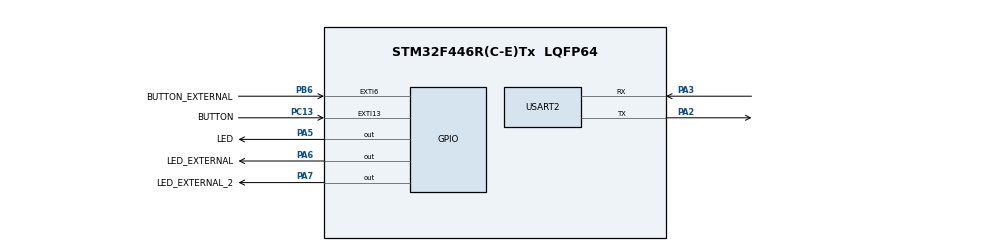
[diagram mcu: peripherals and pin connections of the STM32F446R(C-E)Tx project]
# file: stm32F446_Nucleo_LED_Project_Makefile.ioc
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Mcu.Family=STM32F4
Mcu.Name=STM32F446R(C-E)Tx
Mcu.Package=LQFP64
NVIC.EXTI15_10_IRQn=true\:0\:0\:false\:false\:true\:true
NVIC.EXTI9_5_IRQn=true\:0\:0\:false\:false\:true\:true
NVIC.PriorityGroup=NVIC_PRIORITYGROUP_4
NVIC.TIM6_DAC_IRQn=true\:0\:0\:false\:false\:true\:true
NVIC.USART2_IRQn=true\:0\:0\:false\:false\:true\:true
PA2.Mode=Asynchronous
PA2.Signal=USART2_TX
PA3.Mode=Asynchronous
PA3.Signal=USART2_RX
PA5.GPIO_Label=LED
PA5.Signal=GPIO_Output
PA6.GPIO_Label=LED_EXTERNAL
PA6.Signal=GPIO_Output
PA7.GPIO_Label=LED_EXTERNAL_2
PA7.Signal=GPIO_Output
PB6.GPIO_Label=BUTTON_EXTERNAL
PB6.GPIO_ModeDefaultEXTI=GPIO_MODE_IT_FALLING
PB6.GPIO_PuPd=GPIO_PULLUP
PB6.Signal=GPXTI6
PC13.GPIO_Label=BUTTON
PC13.GPIO_ModeDefaultEXTI=GPIO_MODE_IT_FALLING
PC13.Signal=GPXTI13
ProjectManager.HeapSize=0x200
ProjectManager.StackSize=0x400
ProjectManager.TargetToolchain=Makefile
RCC.CortexFreq_Value=16000000
RCC.USBFreq_Value=96000000
RCC.VCOOutputFreq_Value=192000000
TIM6.Period=499
TIM6.Prescaler=15999
USART2.VirtualMode=VM_ASYNC
VP_TIM6_VS_ClockSourceINT.Mode=Enable_Timer
board=custom

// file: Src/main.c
/**
  ******************************************************************************
  * @file           : main.c
  * @brief          : Main program body
  ******************************************************************************
  ** This notice applies to any and all portions of this file
  * that are not between comment pairs USER CODE BEGIN and
  * USER CODE END. Other portions of this file, whether
  * inserted by the user or by software development tools
  * are owned by their respective copyright owners.
  *
  * COPYRIGHT(c) 2018 STMicroelectronics
  *
  * Redistribution and use in source and binary forms, with or without modification,
  * are permitted provided that the following conditions are met:
  *   1. Redistributions of source code must retain the above copyright notice,
  *      this list of conditions and the following disclaimer.
  *   2. Redistributions in binary form must reproduce the above copyright notice,
  *      this list of conditions and the following disclaimer in the documentation
  *      and/or other materials provided with the distribution.
  *   3. Neither the name of STMicroelectronics nor the names of its contributors
  *      may be used to endorse or promote products derived from this software
  *      without specific prior written permission.
  *
  * THIS SOFTWARE IS PROVIDED BY THE COPYRIGHT HOLDERS AND CONTRIBUTORS "AS IS"
  * AND ANY EXPRESS OR IMPLIED WARRANTIES, INCLUDING, BUT NOT LIMITED TO, THE
  * IMPLIED WARRANTIES OF MERCHANTABILITY AND FITNESS FOR A PARTICULAR PURPOSE ARE
  * DISCLAIMED. IN NO EVENT SHALL THE COPYRIGHT HOLDER OR CONTRIBUTORS BE LIABLE
  * FOR ANY DIRECT, INDIRECT, INCIDENTAL, SPECIAL, EXEMPLARY, OR CONSEQUENTIAL
  * DAMAGES (INCLUDING, BUT NOT LIMITED TO, PROCUREMENT OF SUBSTITUTE GOODS OR
  * SERVICES; LOSS OF USE, DATA, OR PROFITS; OR BUSINESS INTERRUPTION) HOWEVER
  * CAUSED AND ON ANY THEORY OF LIABILITY, WHETHER IN CONTRACT, STRICT LIABILITY,
  * OR TORT (INCLUDING NEGLIGENCE OR OTHERWISE) ARISING IN ANY WAY OUT OF THE USE
  * OF THIS SOFTWARE, EVEN IF ADVISED OF THE POSSIBILITY OF SUCH DAMAGE.
  *
  ******************************************************************************
  */
#include "main.h"
#include "stm32f4xx_hal.h"

TIM_HandleTypeDef htim6;

UART_HandleTypeDef huart2;

/* USER CODE BEGIN PV */
/* Private variables ---------------------------------------------------------*/
extern void BOOT_Init(void);
extern void BOOT_LoopStart(void);
/* USER CODE END PV */

void SystemClock_Config(void);
static void MX_GPIO_Init(void);
static void MX_USART2_UART_Init(void);
static void MX_TIM6_Init(void);

/* USER CODE BEGIN PFP */
/* Private function prototypes -----------------------------------------------*/

/* USER CODE END PFP */

int main(void)
{

  /* MCU Configuration--------------------------------------------------------*/

  /* Reset of all peripherals, Initializes the Flash interface and the Systick. */
  HAL_Init();

  /* Configure the system clock */
  SystemClock_Config();

  /* Initialize all configured peripherals */
  MX_GPIO_Init();
  MX_USART2_UART_Init();
  MX_TIM6_Init();

  /* USER CODE BEGIN 2 */
  BOOT_Init();

  /* USER CODE END 2 */

  /* Infinite loop */
  /* USER CODE BEGIN WHILE */
  BOOT_LoopStart();

  /* USER CODE END WHILE */

}

void SystemClock_Config(void)
{

  RCC_OscInitTypeDef RCC_OscInitStruct;
  RCC_ClkInitTypeDef RCC_ClkInitStruct;

    /**Configure the main internal regulator output voltage
    */
  __HAL_RCC_PWR_CLK_ENABLE();

  __HAL_PWR_VOLTAGESCALING_CONFIG(PWR_REGULATOR_VOLTAGE_SCALE3);

    /**Initializes the CPU, AHB and APB busses clocks
    */
  RCC_OscInitStruct.OscillatorType = RCC_OSCILLATORTYPE_HSI;
  RCC_OscInitStruct.HSIState = RCC_HSI_ON;
  RCC_OscInitStruct.HSICalibrationValue = 16;
  RCC_OscInitStruct.PLL.PLLState = RCC_PLL_NONE;
  if (HAL_RCC_OscConfig(&RCC_OscInitStruct) != HAL_OK)
  {
    _Error_Handler(__FILE__, __LINE__);
  }

    /**Initializes the CPU, AHB and APB busses clocks
    */
  RCC_ClkInitStruct.ClockType = RCC_CLOCKTYPE_HCLK|RCC_CLOCKTYPE_SYSCLK
                              |RCC_CLOCKTYPE_PCLK1|RCC_CLOCKTYPE_PCLK2;
  RCC_ClkInitStruct.SYSCLKSource = RCC_SYSCLKSOURCE_HSI;
  RCC_ClkInitStruct.AHBCLKDivider = RCC_SYSCLK_DIV1;
  RCC_ClkInitStruct.APB1CLKDivider = RCC_HCLK_DIV1;
  RCC_ClkInitStruct.APB2CLKDivider = RCC_HCLK_DIV1;

  if (HAL_RCC_ClockConfig(&RCC_ClkInitStruct, FLASH_LATENCY_0) != HAL_OK)
  {
    _Error_Handler(__FILE__, __LINE__);
  }

    /**Configure the Systick interrupt time
    */
  HAL_SYSTICK_Config(HAL_RCC_GetHCLKFreq()/1000);

    /**Configure the Systick
    */
  HAL_SYSTICK_CLKSourceConfig(SYSTICK_CLKSOURCE_HCLK);

  /* SysTick_IRQn interrupt configuration */
  HAL_NVIC_SetPriority(SysTick_IRQn, 0, 0);
}

/* TIM6 init function */
static void MX_TIM6_Init(void)
{

  TIM_MasterConfigTypeDef sMasterConfig;

  htim6.Instance = TIM6;
  htim6.Init.Prescaler = 15999;
  htim6.Init.CounterMode = TIM_COUNTERMODE_UP;
  htim6.Init.Period = 499;
  if (HAL_TIM_Base_Init(&htim6) != HAL_OK)
  {
    _Error_Handler(__FILE__, __LINE__);
  }

  sMasterConfig.MasterOutputTrigger = TIM_TRGO_RESET;
  sMasterConfig.MasterSlaveMode = TIM_MASTERSLAVEMODE_DISABLE;
  if (HAL_TIMEx_MasterConfigSynchronization(&htim6, &sMasterConfig) != HAL_OK)
  {
    _Error_Handler(__FILE__, __LINE__);
  }

}

/* USART2 init function */
static void MX_USART2_UART_Init(void)
{

  huart2.Instance = USART2;
  huart2.Init.BaudRate = 115200;
  huart2.Init.WordLength = UART_WORDLENGTH_8B;
  huart2.Init.StopBits = UART_STOPBITS_1;
  huart2.Init.Parity = UART_PARITY_NONE;
  huart2.Init.Mode = UART_MODE_TX_RX;
  huart2.Init.HwFlowCtl = UART_HWCONTROL_NONE;
  huart2.Init.OverSampling = UART_OVERSAMPLING_16;
  if (HAL_UART_Init(&huart2) != HAL_OK)
  {
    _Error_Handler(__FILE__, __LINE__);
  }

}

/** Configure pins as
        * Analog
        * Input
        * Output
        * EVENT_OUT
        * EXTI
*/
static void MX_GPIO_Init(void)
{

  GPIO_InitTypeDef GPIO_InitStruct;

  /* GPIO Ports Clock Enable */
  __HAL_RCC_GPIOC_CLK_ENABLE();
  __HAL_RCC_GPIOA_CLK_ENABLE();
  __HAL_RCC_GPIOB_CLK_ENABLE();

  /*Configure GPIO pin Output Level */
  HAL_GPIO_WritePin(GPIOA, LED_Pin|LED_EXTERNAL_Pin|LED_EXTERNAL_2_Pin, GPIO_PIN_RESET);

  /*Configure GPIO pin : BUTTON_Pin */
  GPIO_InitStruct.Pin = BUTTON_Pin;
  GPIO_InitStruct.Mode = GPIO_MODE_IT_FALLING;
  GPIO_InitStruct.Pull = GPIO_NOPULL;
  HAL_GPIO_Init(BUTTON_GPIO_Port, &GPIO_InitStruct);

  /*Configure GPIO pins : LED_Pin LED_EXTERNAL_Pin LED_EXTERNAL_2_Pin */
  GPIO_InitStruct.Pin = LED_Pin|LED_EXTERNAL_Pin|LED_EXTERNAL_2_Pin;
  GPIO_InitStruct.Mode = GPIO_MODE_OUTPUT_PP;
  GPIO_InitStruct.Pull = GPIO_NOPULL;
  GPIO_InitStruct.Speed = GPIO_SPEED_FREQ_LOW;
  HAL_GPIO_Init(GPIOA, &GPIO_InitStruct);

  /*Configure GPIO pin : BUTTON_EXTERNAL_Pin */
  GPIO_InitStruct.Pin = BUTTON_EXTERNAL_Pin;
  GPIO_InitStruct.Mode = GPIO_MODE_IT_FALLING;
  GPIO_InitStruct.Pull = GPIO_PULLUP;
  HAL_GPIO_Init(BUTTON_EXTERNAL_GPIO_Port, &GPIO_InitStruct);

  /* EXTI interrupt init*/
  HAL_NVIC_SetPriority(EXTI9_5_IRQn, 0, 0);
  HAL_NVIC_EnableIRQ(EXTI9_5_IRQn);

  HAL_NVIC_SetPriority(EXTI15_10_IRQn, 0, 0);
  HAL_NVIC_EnableIRQ(EXTI15_10_IRQn);

}

/* USER CODE BEGIN 4 */

void HAL_GPIO_EXTI_Callback(uint16_t GPIO_Pin)
{
  void;
}

/* USER CODE END 4 */

void _Error_Handler(char *file, int line)
{
  while(1)
    {
    }
}

/************************ (C) COPYRIGHT STMicroelectronics *****END OF FILE****/
